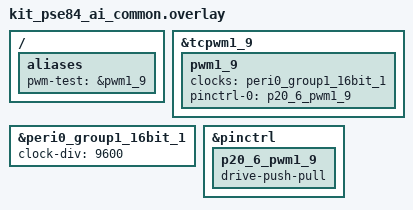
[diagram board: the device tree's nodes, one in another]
/*
 * SPDX-FileCopyrightText: Copyright (c) 2026 Infineon Technologies AG,
 * SPDX-FileCopyrightText: or an affiliate of Infineon Technologies AG. All rights reserved.
 *
 * SPDX-License-Identifier: Apache-2.0
 */

#include <zephyr/dt-bindings/pwm/pwm.h>
#include <zephyr/dt-bindings/pwm/pwm_ifx_tcpwm.h>

/ {
	aliases {
		pwm-test = &pwm1_9;
	};
};

&tcpwm1_9 {
	status = "okay";

	pwm1_9: pwm1_9 {
		clocks = <&peri0_group1_16bit_1>;
		pinctrl-0 = <&p20_6_pwm1_9>;
		pinctrl-names = "default";
		status = "okay";
	};
};

&peri0_group1_16bit_1 {
	clock-div = <9600>;
	status = "okay";
};

&pinctrl {
	p20_6_pwm1_9: p20_6_pwm1_9 {
		drive-push-pull;
	};
};
